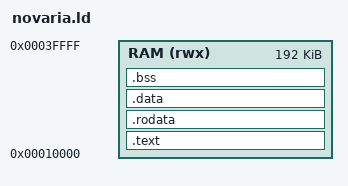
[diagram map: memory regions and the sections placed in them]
OUTPUT_ARCH(riscv)
ENTRY(_start)

MEMORY {
    RAM (rwx) : ORIGIN = 0x10000, LENGTH = 0x30000
}

SECTIONS {
    .text : {
        *(.text .text.*)
    } > RAM

    .rodata : {
        *(.rodata .rodata.*)
    } > RAM

    .data : {
        *(.data .data.*)
        *(.sdata .sdata.*)
    } > RAM

    .bss (NOLOAD) : {
        __bss_start = .;
        *(.bss .bss.*)
        *(.sbss .sbss.*)
        *(COMMON)
        . = ALIGN(8);
        __bss_end = .;
    } > RAM

    /DISCARD/ : {
        *(.eh_frame)
        *(.comment)
        *(.riscv.attributes)
    }
}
